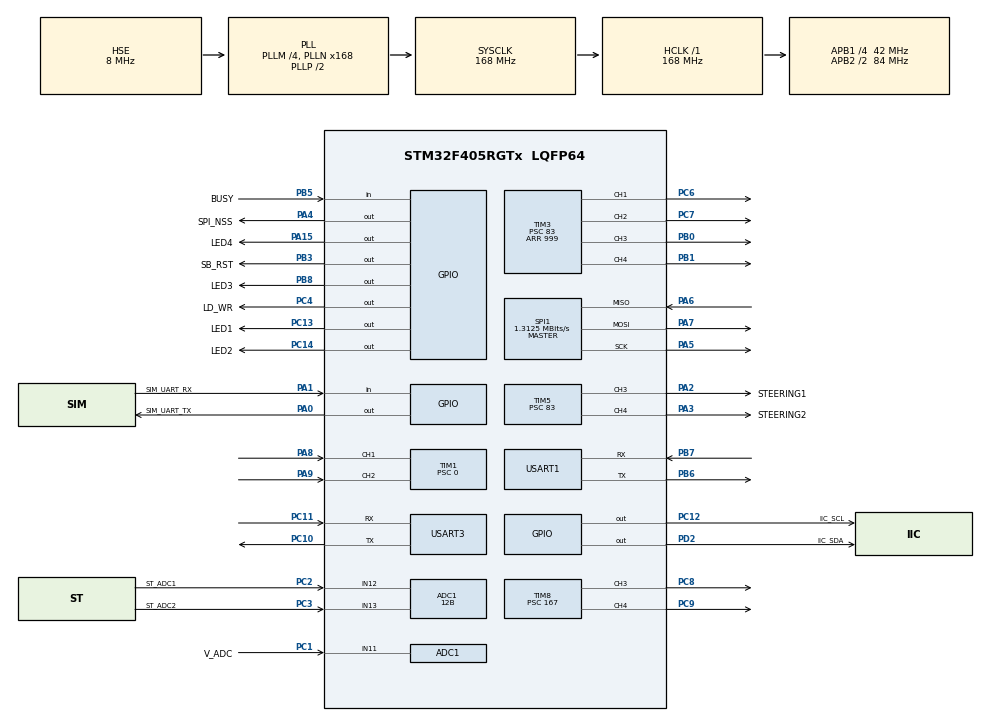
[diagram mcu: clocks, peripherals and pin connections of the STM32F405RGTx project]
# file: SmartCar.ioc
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ADC1.Channel-0\#ChannelRegularConversion=ADC_CHANNEL_11
ADC1.Channel-1\#ChannelRegularConversion=ADC_CHANNEL_12
ADC1.Channel-2\#ChannelRegularConversion=ADC_CHANNEL_13
ADC1.ClockPrescaler=ADC_CLOCK_SYNC_PCLK_DIV4
ADC1.ContinuousConvMode=ENABLE
ADC1.DMAContinuousRequests=ENABLE
ADC1.DataAlign=ADC_DATAALIGN_RIGHT
ADC1.DiscontinuousConvMode=DISABLE
ADC1.EOCSelection=ADC_EOC_SINGLE_CONV
ADC1.EnableAnalogWatchDog=false
ADC1.ExternalTrigConv=ADC_SOFTWARE_START
ADC1.ExternalTrigConvEdge=ADC_EXTERNALTRIGCONVEDGE_NONE
ADC1.InjNumberOfConversion=0
ADC1.NbrOfConversion=3
ADC1.NbrOfConversionFlag=1
ADC1.Rank-0\#ChannelRegularConversion=1
ADC1.Rank-1\#ChannelRegularConversion=2
ADC1.Rank-2\#ChannelRegularConversion=3
ADC1.Resolution=ADC_RESOLUTION_12B
ADC1.SamplingTime-0\#ChannelRegularConversion=ADC_SAMPLETIME_15CYCLES
ADC1.SamplingTime-1\#ChannelRegularConversion=ADC_SAMPLETIME_15CYCLES
ADC1.SamplingTime-2\#ChannelRegularConversion=ADC_SAMPLETIME_15CYCLES
ADC1.ScanConvMode=ENABLE
ADC1.master=1
Dma.ADC1.0.Direction=DMA_PERIPH_TO_MEMORY
Dma.ADC1.0.FIFOMode=DMA_FIFOMODE_DISABLE
Dma.ADC1.0.Instance=DMA2_Stream0
Dma.ADC1.0.MemDataAlignment=DMA_MDATAALIGN_WORD
Dma.ADC1.0.MemInc=DMA_MINC_ENABLE
Dma.ADC1.0.Mode=DMA_CIRCULAR
Dma.ADC1.0.PeriphDataAlignment=DMA_PDATAALIGN_WORD
Dma.ADC1.0.PeriphInc=DMA_PINC_DISABLE
Dma.ADC1.0.Priority=DMA_PRIORITY_LOW
Dma.Request0=ADC1
Dma.Request1=USART3_RX
Dma.Request2=USART1_RX
Dma.USART1_RX.2.Direction=DMA_PERIPH_TO_MEMORY
Dma.USART1_RX.2.FIFOMode=DMA_FIFOMODE_DISABLE
Dma.USART1_RX.2.Instance=DMA2_Stream2
Dma.USART1_RX.2.MemDataAlignment=DMA_MDATAALIGN_BYTE
Dma.USART1_RX.2.MemInc=DMA_MINC_ENABLE
Dma.USART1_RX.2.Mode=DMA_NORMAL
Dma.USART1_RX.2.PeriphDataAlignment=DMA_PDATAALIGN_BYTE
Dma.USART1_RX.2.PeriphInc=DMA_PINC_DISABLE
Dma.USART1_RX.2.Priority=DMA_PRIORITY_LOW
Dma.USART3_RX.1.Direction=DMA_PERIPH_TO_MEMORY
Dma.USART3_RX.1.FIFOMode=DMA_FIFOMODE_DISABLE
Dma.USART3_RX.1.Instance=DMA1_Stream1
Dma.USART3_RX.1.MemDataAlignment=DMA_MDATAALIGN_BYTE
Dma.USART3_RX.1.MemInc=DMA_MINC_ENABLE
Dma.USART3_RX.1.Mode=DMA_NORMAL
Dma.USART3_RX.1.PeriphDataAlignment=DMA_PDATAALIGN_BYTE
Dma.USART3_RX.1.PeriphInc=DMA_PINC_DISABLE
Dma.USART3_RX.1.Priority=DMA_PRIORITY_LOW
FREERTOS.Tasks01=StartTask,0,256,Start_Task,As weak,NULL,Dynamic,NULL,NULL
FREERTOS.configTOTAL_HEAP_SIZE=50000
Mcu.Family=STM32F4
Mcu.Name=STM32F405RGTx
Mcu.Package=LQFP64
NVIC.ADC_IRQn=true\:5\:0\:false\:false\:true\:true\:true
NVIC.DMA1_Stream1_IRQn=true\:5\:0\:false\:false\:true\:true\:false
NVIC.DMA2_Stream0_IRQn=true\:5\:0\:false\:false\:true\:true\:false
NVIC.DMA2_Stream2_IRQn=true\:5\:0\:false\:false\:true\:true\:false
NVIC.PriorityGroup=NVIC_PRIORITYGROUP_4
NVIC.TIM8_TRG_COM_TIM14_IRQn=true\:0\:0\:false\:false\:true\:false\:false
NVIC.TimeBase=TIM8_TRG_COM_TIM14_IRQn
NVIC.TimeBaseIP=TIM14
NVIC.USART1_IRQn=true\:5\:0\:false\:false\:true\:true\:true
NVIC.USART3_IRQn=true\:5\:0\:false\:false\:true\:true\:true
PA0-WKUP.GPIO_Label=SIM_UART_TX
PA0-WKUP.Signal=GPIO_Output
PA1.GPIO_Label=SIM_UART_RX
PA1.Signal=GPIO_Input
PA13.Mode=Serial_Wire
PA13.Signal=SYS_JTMS-SWDIO
PA14.Mode=Serial_Wire
PA14.Signal=SYS_JTCK-SWCLK
PA15.GPIO_Label=LED4
PA15.Signal=GPIO_Output
PA2.GPIO_Label=STEERING1
PA2.Signal=S_TIM5_CH3
PA3.GPIO_Label=STEERING2
PA3.Signal=S_TIM5_CH4
PA4.GPIO_Label=SPI_NSS
PA4.Signal=GPIO_Output
PA5.Mode=Full_Duplex_Master
PA5.Signal=SPI1_SCK
PA6.Mode=Full_Duplex_Master
PA6.Signal=SPI1_MISO
PA7.Mode=Full_Duplex_Master
PA7.Signal=SPI1_MOSI
PA8.Signal=S_TIM1_CH1
PA9.Signal=S_TIM1_CH2
PB0.Signal=S_TIM3_CH3
PB1.Signal=S_TIM3_CH4
PB3.GPIO_Label=SB_RST
PB3.Signal=GPIO_Output
PB5.GPIO_Label=BUSY
PB5.Signal=GPIO_Input
PB6.Mode=Asynchronous
PB6.Signal=USART1_TX
PB7.Mode=Asynchronous
PB7.Signal=USART1_RX
PB8.GPIO_Label=LED3
PB8.Signal=GPIO_Output
PC1.GPIO_Label=V_ADC
PC1.Signal=ADCx_IN11
PC10.Mode=Asynchronous
PC10.Signal=USART3_TX
PC11.Mode=Asynchronous
PC11.Signal=USART3_RX
PC12.GPIO_Label=IIC_SCL
PC12.Signal=GPIO_Output
PC13-ANTI_TAMP.GPIO_Label=LED1
PC13-ANTI_TAMP.Signal=GPIO_Output
PC14-OSC32_IN.GPIO_Label=LED2
PC14-OSC32_IN.Signal=GPIO_Output
PC2.GPIO_Label=ST_ADC1
PC2.Signal=ADCx_IN12
PC3.GPIO_Label=ST_ADC2
PC3.Signal=ADCx_IN13
PC4.GPIO_Label=LD_WR
PC4.Signal=GPIO_Output
PC6.Signal=S_TIM3_CH1
PC7.Signal=S_TIM3_CH2
PC8.Signal=S_TIM8_CH3
PC9.Signal=S_TIM8_CH4
PD2.GPIO_Label=IIC_SDA
PD2.Signal=GPIO_Output
PH0-OSC_IN.Mode=HSE-External-Oscillator
PH0-OSC_IN.Signal=RCC_OSC_IN
PH1-OSC_OUT.Mode=HSE-External-Oscillator
PH1-OSC_OUT.Signal=RCC_OSC_OUT
ProjectManager.HeapSize=0x200
ProjectManager.StackSize=0x400
ProjectManager.TargetToolchain=MDK-ARM V5
RCC.48MHZClocksFreq_Value=48000000
RCC.AHBFreq_Value=168000000
RCC.APB1CLKDivider=RCC_HCLK_DIV4
RCC.APB1Freq_Value=42000000
RCC.APB1TimFreq_Value=84000000
RCC.APB2CLKDivider=RCC_HCLK_DIV2
RCC.APB2Freq_Value=84000000
RCC.APB2TimFreq_Value=168000000
RCC.CortexFreq_Value=168000000
RCC.HCLKFreq_Value=168000000
RCC.HSE_VALUE=8000000
RCC.HSI_VALUE=16000000
RCC.LSE_VALUE=32768
RCC.PLLM=4
RCC.PLLN=168
RCC.PLLQ=7
RCC.PLLSourceVirtual=RCC_PLLSOURCE_HSE
RCC.SYSCLKFreq_VALUE=168000000
RCC.SYSCLKSource=RCC_SYSCLKSOURCE_PLLCLK
RCC.VCOOutputFreq_Value=336000000
SH.ADCx_IN11.0=ADC1_IN11,IN11
SH.ADCx_IN12.0=ADC1_IN12,IN12
SH.ADCx_IN13.0=ADC1_IN13,IN13
SH.S_TIM1_CH1.0=TIM1_CH1,Encoder_Interface
SH.S_TIM1_CH2.0=TIM1_CH2,Encoder_Interface
SH.S_TIM3_CH1.0=TIM3_CH1,PWM Generation1 CH1
SH.S_TIM3_CH2.0=TIM3_CH2,PWM Generation2 CH2
SH.S_TIM3_CH3.0=TIM3_CH3,PWM Generation3 CH3
SH.S_TIM3_CH4.0=TIM3_CH4,PWM Generation4 CH4
SH.S_TIM5_CH3.0=TIM5_CH3,PWM Generation3 CH3
SH.S_TIM5_CH4.0=TIM5_CH4,PWM Generation4 CH4
SH.S_TIM8_CH3.0=TIM8_CH3,PWM Generation3 CH3
SH.S_TIM8_CH4.0=TIM8_CH4,PWM Generation4 CH4
SPI1.BaudRatePrescaler=SPI_BAUDRATEPRESCALER_64
SPI1.CLKPolarity=SPI_POLARITY_HIGH
SPI1.CalculateBaudRate=1.3125 MBits/s
SPI1.Direction=SPI_DIRECTION_2LINES
SPI1.Mode=SPI_MODE_MASTER
SPI1.VirtualType=VM_MASTER
TIM1.Period=65535
TIM1.Prescaler=0
TIM10.Period=65535
TIM10.Prescaler=880
TIM3.Channel-PWM\ Generation1\ CH1=TIM_CHANNEL_1
TIM3.Channel-PWM\ Generation2\ CH2=TIM_CHANNEL_2
TIM3.Channel-PWM\ Generation3\ CH3=TIM_CHANNEL_3
TIM3.Channel-PWM\ Generation4\ CH4=TIM_CHANNEL_4
TIM3.Period=999
TIM3.Prescaler=83
TIM5.Channel-PWM\ Generation3\ CH3=TIM_CHANNEL_3
TIM5.Channel-PWM\ Generation4\ CH4=TIM_CHANNEL_4
TIM5.Period=19999
TIM5.Prescaler=83
TIM8.Channel-PWM\ Generation3\ CH3=TIM_CHANNEL_3
TIM8.Channel-PWM\ Generation4\ CH4=TIM_CHANNEL_4
TIM8.Period=999
TIM8.Prescaler=167
USART1.VirtualMode=VM_ASYNC
USART3.VirtualMode=VM_ASYNC
VP_FREERTOS_VS_ENABLE.Mode=Enabled
VP_RNG_VS_RNG.Mode=RNG_Activate
VP_SYS_VS_tim14.Mode=TIM14
VP_TIM10_VS_ClockSourceINT.Mode=Enable_Timer
board=custom

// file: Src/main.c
/**
  ******************************************************************************
  * @file           : main.c
  * @brief          : Main program body
  ******************************************************************************
  * This notice applies to any and all portions of this file
  * that are not between comment pairs USER CODE BEGIN and
  * USER CODE END. Other portions of this file, whether
  * inserted by the user or by software development tools
  * are owned by their respective copyright owners.
  *
  * Copyright (c) 2019 STMicroelectronics International N.V.
  * All rights reserved.
  *
  * Redistribution and use in source and binary forms, with or without
  * modification, are permitted, provided that the following conditions are met:
  *
  * 1. Redistribution of source code must retain the above copyright notice,
  *    this list of conditions and the following disclaimer.
  * 2. Redistributions in binary form must reproduce the above copyright notice,
  *    this list of conditions and the following disclaimer in the documentation
  *    and/or other materials provided with the distribution.
  * 3. Neither the name of STMicroelectronics nor the names of other
  *    contributors to this software may be used to endorse or promote products
  *    derived from this software without specific written permission.
  * 4. This software, including modifications and/or derivative works of this
  *    software, must execute solely and exclusively on microcontroller or
  *    microprocessor devices manufactured by or for STMicroelectronics.
  * 5. Redistribution and use of this software other than as permitted under
  *    this license is void and will automatically terminate your rights under
  *    this license.
  *
  * THIS SOFTWARE IS PROVIDED BY STMICROELECTRONICS AND CONTRIBUTORS "AS IS"
  * AND ANY EXPRESS, IMPLIED OR STATUTORY WARRANTIES, INCLUDING, BUT NOT
  * LIMITED TO, THE IMPLIED WARRANTIES OF MERCHANTABILITY, FITNESS FOR A
  * PARTICULAR PURPOSE AND NON-INFRINGEMENT OF THIRD PARTY INTELLECTUAL PROPERTY
  * RIGHTS ARE DISCLAIMED TO THE FULLEST EXTENT PERMITTED BY LAW. IN NO EVENT
  * SHALL STMICROELECTRONICS OR CONTRIBUTORS BE LIABLE FOR ANY DIRECT, INDIRECT,
  * INCIDENTAL, SPECIAL, EXEMPLARY, OR CONSEQUENTIAL DAMAGES (INCLUDING, BUT NOT
  * LIMITED TO, PROCUREMENT OF SUBSTITUTE GOODS OR SERVICES; LOSS OF USE, DATA,
  * OR PROFITS; OR BUSINESS INTERRUPTION) HOWEVER CAUSED AND ON ANY THEORY OF
  * LIABILITY, WHETHER IN CONTRACT, STRICT LIABILITY, OR TORT (INCLUDING
  * NEGLIGENCE OR OTHERWISE) ARISING IN ANY WAY OUT OF THE USE OF THIS SOFTWARE,
  * EVEN IF ADVISED OF THE POSSIBILITY OF SUCH DAMAGE.
  *
  ******************************************************************************
  */
#include "main.h"
#include "stm32f4xx_hal.h"
#include "cmsis_os.h"
#include "adc.h"
#include "dma.h"
#include "rng.h"
#include "spi.h"
#include "tim.h"
#include "usart.h"
#include "gpio.h"

/* USER CODE BEGIN Includes */
#include "bsp.h"
/* USER CODE END Includes */

/* USER CODE BEGIN PV */
/* Private variables ---------------------------------------------------------*/

/* USER CODE END PV */

void SystemClock_Config(void);
void MX_FREERTOS_Init(void);

/* USER CODE BEGIN PFP */
/* Private function prototypes -----------------------------------------------*/

/* USER CODE END PFP */

int main(void)
{

  /* MCU Configuration----------------------------------------------------------*/

  /* Reset of all peripherals, Initializes the Flash interface and the Systick. */
  HAL_Init();

  /* Configure the system clock */
  SystemClock_Config();

  /* Initialize all configured peripherals */
  MX_GPIO_Init();
  MX_DMA_Init();
  MX_ADC1_Init();
  MX_SPI1_Init();
  MX_USART3_UART_Init();
  MX_USART1_UART_Init();
  MX_TIM3_Init();
  MX_TIM1_Init();
  MX_TIM8_Init();
  MX_TIM5_Init();
  MX_TIM10_Init();
  MX_RNG_Init();
  /* USER CODE BEGIN 2 */
  BSP_Init();
  /* USER CODE END 2 */

  /* Call init function for freertos objects (in freertos.c) */
  MX_FREERTOS_Init();

  /* Start scheduler */
  osKernelStart();

  /* We should never get here as control is now taken by the scheduler */

  /* Infinite loop */
  while (1)
  {

  }

}

void SystemClock_Config(void)
{

  RCC_OscInitTypeDef RCC_OscInitStruct;
  RCC_ClkInitTypeDef RCC_ClkInitStruct;

    /**Configure the main internal regulator output voltage
    */
  __HAL_RCC_PWR_CLK_ENABLE();

  __HAL_PWR_VOLTAGESCALING_CONFIG(PWR_REGULATOR_VOLTAGE_SCALE1);

    /**Initializes the CPU, AHB and APB busses clocks
    */
  RCC_OscInitStruct.OscillatorType = RCC_OSCILLATORTYPE_HSE;
  RCC_OscInitStruct.HSEState = RCC_HSE_ON;
  RCC_OscInitStruct.PLL.PLLState = RCC_PLL_ON;
  RCC_OscInitStruct.PLL.PLLSource = RCC_PLLSOURCE_HSE;
  RCC_OscInitStruct.PLL.PLLM = 4;
  RCC_OscInitStruct.PLL.PLLN = 168;
  RCC_OscInitStruct.PLL.PLLP = RCC_PLLP_DIV2;
  RCC_OscInitStruct.PLL.PLLQ = 7;
  if (HAL_RCC_OscConfig(&RCC_OscInitStruct) != HAL_OK)
  {
    _Error_Handler(__FILE__, __LINE__);
  }

    /**Initializes the CPU, AHB and APB busses clocks
    */
  RCC_ClkInitStruct.ClockType = RCC_CLOCKTYPE_HCLK|RCC_CLOCKTYPE_SYSCLK
                              |RCC_CLOCKTYPE_PCLK1|RCC_CLOCKTYPE_PCLK2;
  RCC_ClkInitStruct.SYSCLKSource = RCC_SYSCLKSOURCE_PLLCLK;
  RCC_ClkInitStruct.AHBCLKDivider = RCC_SYSCLK_DIV1;
  RCC_ClkInitStruct.APB1CLKDivider = RCC_HCLK_DIV4;
  RCC_ClkInitStruct.APB2CLKDivider = RCC_HCLK_DIV2;

  if (HAL_RCC_ClockConfig(&RCC_ClkInitStruct, FLASH_LATENCY_5) != HAL_OK)
  {
    _Error_Handler(__FILE__, __LINE__);
  }

    /**Configure the Systick interrupt time
    */
  HAL_SYSTICK_Config(HAL_RCC_GetHCLKFreq()/1000);

    /**Configure the Systick
    */
  HAL_SYSTICK_CLKSourceConfig(SYSTICK_CLKSOURCE_HCLK);

  /* SysTick_IRQn interrupt configuration */
  HAL_NVIC_SetPriority(SysTick_IRQn, 15, 0);
}

void HAL_TIM_PeriodElapsedCallback(TIM_HandleTypeDef *htim)
{
  if (htim->Instance == TIM14) {
    HAL_IncTick();
  }
}

void _Error_Handler(char *file, int line)
{
  while(1)
  {
  }
}

/************************ (C) COPYRIGHT STMicroelectronics *****END OF FILE****/

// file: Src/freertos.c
/* USER CODE BEGIN Header */
/**
  ******************************************************************************
  * File Name          : freertos.c
  * Description        : Code for freertos applications
  ******************************************************************************
  * This notice applies to any and all portions of this file
  * that are not between comment pairs USER CODE BEGIN and
  * USER CODE END. Other portions of this file, whether
  * inserted by the user or by software development tools
  * are owned by their respective copyright owners.
  *
  * Copyright (c) 2018 STMicroelectronics International N.V.
  * All rights reserved.
  *
  * Redistribution and use in source and binary forms, with or without
  * modification, are permitted, provided that the following conditions are met:
  *
  * 1. Redistribution of source code must retain the above copyright notice,
  *    this list of conditions and the following disclaimer.
  * 2. Redistributions in binary form must reproduce the above copyright notice,
  *    this list of conditions and the following disclaimer in the documentation
  *    and/or other materials provided with the distribution.
  * 3. Neither the name of STMicroelectronics nor the names of other
  *    contributors to this software may be used to endorse or promote products
  *    derived from this software without specific written permission.
  * 4. This software, including modifications and/or derivative works of this
  *    software, must execute solely and exclusively on microcontroller or
  *    microprocessor devices manufactured by or for STMicroelectronics.
  * 5. Redistribution and use of this software other than as permitted under
  *    this license is void and will automatically terminate your rights under
  *    this license.
  *
  * THIS SOFTWARE IS PROVIDED BY STMICROELECTRONICS AND CONTRIBUTORS "AS IS"
  * AND ANY EXPRESS, IMPLIED OR STATUTORY WARRANTIES, INCLUDING, BUT NOT
  * LIMITED TO, THE IMPLIED WARRANTIES OF MERCHANTABILITY, FITNESS FOR A
  * PARTICULAR PURPOSE AND NON-INFRINGEMENT OF THIRD PARTY INTELLECTUAL PROPERTY
  * RIGHTS ARE DISCLAIMED TO THE FULLEST EXTENT PERMITTED BY LAW. IN NO EVENT
  * SHALL STMICROELECTRONICS OR CONTRIBUTORS BE LIABLE FOR ANY DIRECT, INDIRECT,
  * INCIDENTAL, SPECIAL, EXEMPLARY, OR CONSEQUENTIAL DAMAGES (INCLUDING, BUT NOT
  * LIMITED TO, PROCUREMENT OF SUBSTITUTE GOODS OR SERVICES; LOSS OF USE, DATA,
  * OR PROFITS; OR BUSINESS INTERRUPTION) HOWEVER CAUSED AND ON ANY THEORY OF
  * LIABILITY, WHETHER IN CONTRACT, STRICT LIABILITY, OR TORT (INCLUDING
  * NEGLIGENCE OR OTHERWISE) ARISING IN ANY WAY OUT OF THE USE OF THIS SOFTWARE,
  * EVEN IF ADVISED OF THE POSSIBILITY OF SUCH DAMAGE.
  *
  ******************************************************************************
  */
/* USER CODE END Header */

#include "FreeRTOS.h"
#include "task.h"
#include "main.h"
#include "cmsis_os.h"

osThreadId StartTaskHandle;

void Start_Task(void const * argument);

void MX_FREERTOS_Init(void); /* (MISRA C 2004 rule 8.1) */

void MX_FREERTOS_Init(void) {

  /* Create the thread(s) */
  /* definition and creation of StartTask */
  osThreadDef(StartTask, Start_Task, osPriorityNormal, 0, 256);
  StartTaskHandle = osThreadCreate(osThread(StartTask), NULL);

}

__weak void Start_Task(void const * argument)
{

  for(;;)
  {
    osDelay(1);
  }
}

/************************ (C) COPYRIGHT STMicroelectronics *****END OF FILE****/
